# LM3S9C97 register map
File version: 7944
Registers are 32-bit, read-write, no defined reset value unless marked. A register's access mark holds for its fields unless they carry their own. Offsets are from the block's base; [hi:lo] are bit positions; {n}, {i} and the like mark numbered series.

## SYSCTL — Register map for SYSCTL peripheral
Base 0x400FE000; register names take the prefix SYSCTL
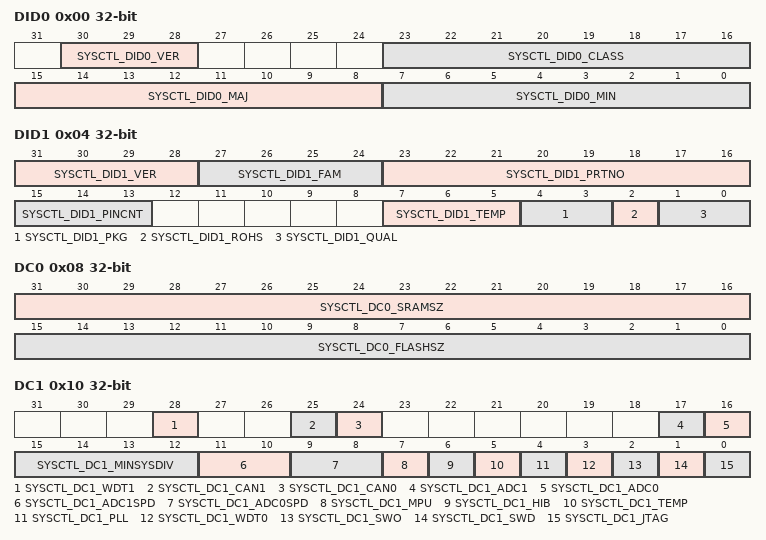
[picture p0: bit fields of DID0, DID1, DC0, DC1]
0x00 DID0 — Device Identification 0
  [30:28] SYSCTL_DID0_VER — DID0 Version
    1=Second version of the DID0 register format
  [23:16] SYSCTL_DID0_CLASS — Device Class
    6=SYSCTL_DID0_CLASS_FIRESTORM (Stellaris(R) Firestorm-class microcontrollers)
  [15:8] SYSCTL_DID0_MAJ — Major Revision
    0=SYSCTL_DID0_MAJ_REVA (Revision A (initial device)); 1=SYSCTL_DID0_MAJ_REVB (Revision B (first base layer revision)); 2=SYSCTL_DID0_MAJ_REVC (Revision C (second base layer revision))
  [7:0] SYSCTL_DID0_MIN — Minor Revision
    0=Initial device, or a major revision update; 1=First metal layer change; 2=Second metal layer change
0x04 DID1 — Device Identification 1
  [31:28] SYSCTL_DID1_VER — DID1 Version
    1=Second version of the DID1 register format
  [27:24] SYSCTL_DID1_FAM — Family
    0=SYSCTL_DID1_FAM_STELLARIS (Stellaris family of microcontollers, that is, all devices with external part numbers starting with LM3S)
  [23:16] SYSCTL_DID1_PRTNO — Part Number
    112=SYSCTL_DID1_PRTNO_9C97 (LM3S9C97)
  [15:13] SYSCTL_DID1_PINCNT — Package Pin Count
    2=100-pin package
  [7:5] SYSCTL_DID1_TEMP — Temperature Range
    0=SYSCTL_DID1_TEMP_C (Commercial temperature range (0C to 70C)); 1=SYSCTL_DID1_TEMP_I (Industrial temperature range (-40C to 85C)); 2=SYSCTL_DID1_TEMP_E (Extended temperature range (-40C to 105C))
  [4:3] SYSCTL_DID1_PKG — Package Type
    0=SYSCTL_DID1_PKG_SOIC (SOIC package); 1=SYSCTL_DID1_PKG_QFP (LQFP package); 2=SYSCTL_DID1_PKG_BGA (BGA package)
  [2] SYSCTL_DID1_ROHS — RoHS-Compliance
  [1:0] SYSCTL_DID1_QUAL — Qualification Status
    0=SYSCTL_DID1_QUAL_ES (Engineering Sample (unqualified)); 1=SYSCTL_DID1_QUAL_PP (Pilot Production (unqualified)); 2=SYSCTL_DID1_QUAL_FQ (Fully Qualified)
0x08 DC0 — Device Capabilities 0
  [31:16] SYSCTL_DC0_SRAMSZ — SRAM Size
    255=SYSCTL_DC0_SRAMSZ_64KB (64 KB of SRAM)
  [15:0] SYSCTL_DC0_FLASHSZ — Flash Size
    255=SYSCTL_DC0_FLASHSZ_512K (512 KB of Flash)
0x10 DC1 — Device Capabilities 1
  [28] SYSCTL_DC1_WDT1 — Watchdog Timer1 Present
  [25] SYSCTL_DC1_CAN1 — CAN Module 1 Present
  [24] SYSCTL_DC1_CAN0 — CAN Module 0 Present
  [17] SYSCTL_DC1_ADC1 — ADC Module 1 Present
  [16] SYSCTL_DC1_ADC0 — ADC Module 0 Present
  [15:12] SYSCTL_DC1_MINSYSDIV — System Clock Divider
    1=Divide VCO (400MHZ) by 5 minimum; 2=Divide VCO (400MHZ) by 2*2 + 2 = 6 minimum; 3=Specifies a 50-MHz CPU clock with a PLL divider of 4; 7=Specifies a 25-MHz clock with a PLL divider of 8; 9=Specifies a 20-MHz clock with a PLL divider of 10
  [11:10] SYSCTL_DC1_ADC1SPD — Max ADC1 Speed
    3=SYSCTL_DC1_ADC1SPD_1M (1M samples/second)
  [9:8] SYSCTL_DC1_ADC0SPD — Max ADC0 Speed
    3=SYSCTL_DC1_ADC0SPD_1M (1M samples/second)
  [7] SYSCTL_DC1_MPU — MPU Present
  [6] SYSCTL_DC1_HIB — Hibernation Module Present
  [5] SYSCTL_DC1_TEMP — Temp Sensor Present
  [4] SYSCTL_DC1_PLL — PLL Present
  [3] SYSCTL_DC1_WDT0 — Watchdog Timer 0 Present
  [2] SYSCTL_DC1_SWO — SWO Trace Port Present
  [1] SYSCTL_DC1_SWD — SWD Present
  [0] SYSCTL_DC1_JTAG — JTAG Present
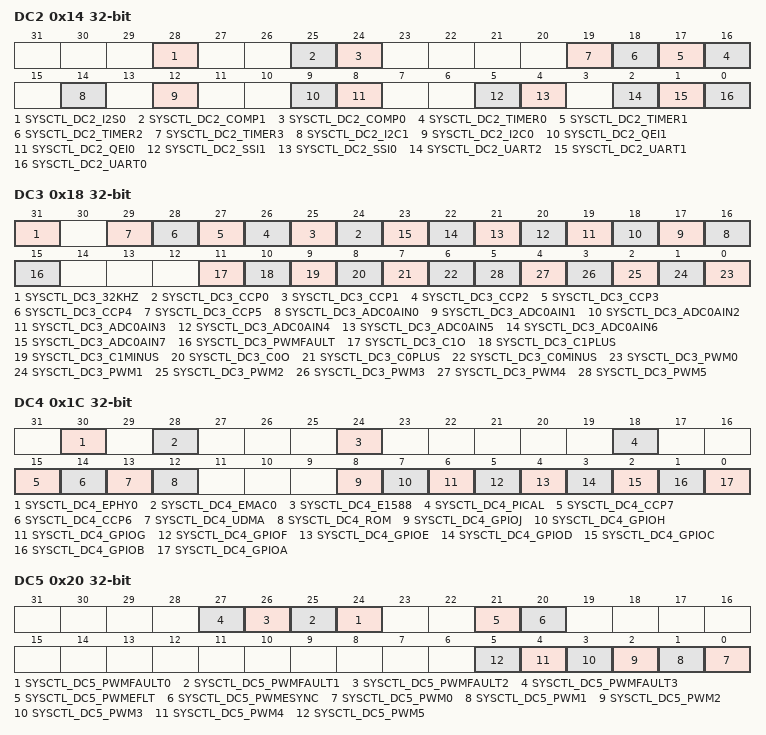
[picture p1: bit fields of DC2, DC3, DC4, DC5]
0x14 DC2 — Device Capabilities 2
  [28] SYSCTL_DC2_I2S0 — I2S Module 0 Present
  [25] SYSCTL_DC2_COMP1 — Analog Comparator 1 Present
  [24] SYSCTL_DC2_COMP0 — Analog Comparator 0 Present
  [n+16] SYSCTL_DC2_TIMER{n} (n=0..3) — Timer Module {n} Present
  [14] SYSCTL_DC2_I2C1 — I2C Module 1 Present
  [12] SYSCTL_DC2_I2C0 — I2C Module 0 Present
  [9] SYSCTL_DC2_QEI1 — QEI Module 1 Present
  [8] SYSCTL_DC2_QEI0 — QEI Module 0 Present
  [5] SYSCTL_DC2_SSI1 — SSI Module 1 Present
  [4] SYSCTL_DC2_SSI0 — SSI Module 0 Present
  [2] SYSCTL_DC2_UART2 — UART Module 2 Present
  [1] SYSCTL_DC2_UART1 — UART Module 1 Present
  [0] SYSCTL_DC2_UART0 — UART Module 0 Present
0x18 DC3 — Device Capabilities 3
  [31] SYSCTL_DC3_32KHZ — 32KHz Input Clock Available
  [n+24] SYSCTL_DC3_CCP{n} (n=0..5) — CCP{n} Pin Present
  [n+16] SYSCTL_DC3_ADC0AIN{n} (n=0..7) — ADC Module 0 AIN{n} Pin Present
  [15] SYSCTL_DC3_PWMFAULT — PWM Fault Pin Present
  [11] SYSCTL_DC3_C1O — C1o Pin Present
  [10] SYSCTL_DC3_C1PLUS — C1+ Pin Present
  [9] SYSCTL_DC3_C1MINUS — C1- Pin Present
  [8] SYSCTL_DC3_C0O — C0o Pin Present
  [7] SYSCTL_DC3_C0PLUS — C0+ Pin Present
  [6] SYSCTL_DC3_C0MINUS — C0- Pin Present
  [n] SYSCTL_DC3_PWM{n} (n=0..5) — PWM{n} Pin Present
0x1C DC4 — Device Capabilities 4
  [30] SYSCTL_DC4_EPHY0 — Ethernet PHY Layer 0 Present
  [28] SYSCTL_DC4_EMAC0 — Ethernet MAC Layer 0 Present
  [24] SYSCTL_DC4_E1588 — 1588 Capable
  [18] SYSCTL_DC4_PICAL — PIOSC Calibrate
  [15] SYSCTL_DC4_CCP7 — CCP7 Pin Present
  [14] SYSCTL_DC4_CCP6 — CCP6 Pin Present
  [13] SYSCTL_DC4_UDMA — Micro-DMA Module Present
  [12] SYSCTL_DC4_ROM — Internal Code ROM Present
  [8] SYSCTL_DC4_GPIOJ — GPIO Port J Present
  [7] SYSCTL_DC4_GPIOH — GPIO Port H Present
  [6] SYSCTL_DC4_GPIOG — GPIO Port G Present
  [5] SYSCTL_DC4_GPIOF — GPIO Port F Present
  [4] SYSCTL_DC4_GPIOE — GPIO Port E Present
  [3] SYSCTL_DC4_GPIOD — GPIO Port D Present
  [2] SYSCTL_DC4_GPIOC — GPIO Port C Present
  [1] SYSCTL_DC4_GPIOB — GPIO Port B Present
  [0] SYSCTL_DC4_GPIOA — GPIO Port A Present
0x20 DC5 — Device Capabilities 5
  [n+24] SYSCTL_DC5_PWMFAULT{n} (n=0..3) — PWM Fault {n} Pin Present
  [21] SYSCTL_DC5_PWMEFLT — PWM Extended Fault Active
  [20] SYSCTL_DC5_PWMESYNC — PWM Extended SYNC Active
  [n] SYSCTL_DC5_PWM{n} (n=0..5) — PWM{n} Pin Present
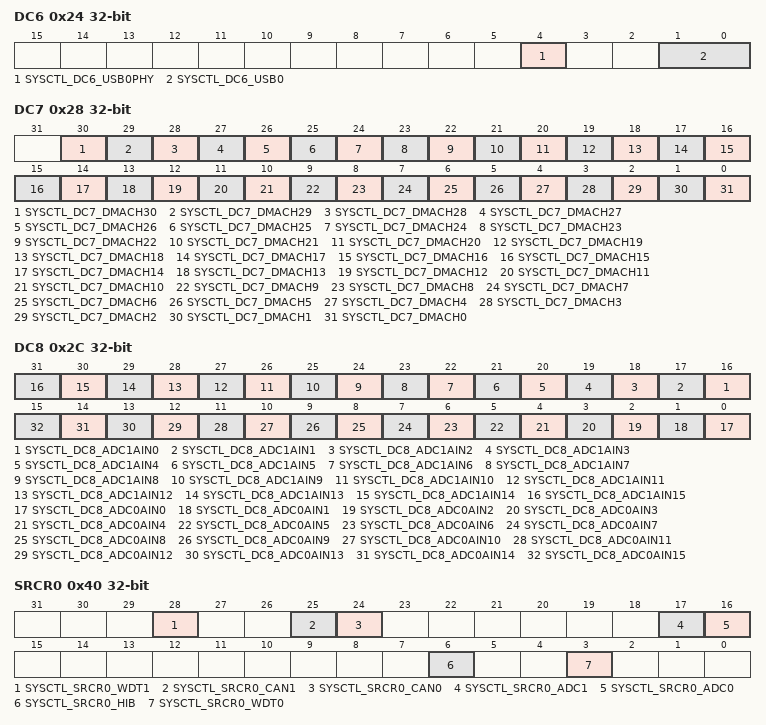
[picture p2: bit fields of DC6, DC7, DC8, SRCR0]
0x24 DC6 — Device Capabilities 6
  [4] SYSCTL_DC6_USB0PHY — USB Module 0 PHY Present
  [1:0] SYSCTL_DC6_USB0 — USB Module 0 Present
    3=SYSCTL_DC6_USB0_OTG (USB0 is OTG)
0x28 DC7 — Device Capabilities 7
  [30] SYSCTL_DC7_DMACH30 — SW
  [29] SYSCTL_DC7_DMACH29 — I2S0_TX / CAN1_TX
  [28] SYSCTL_DC7_DMACH28 — I2S0_RX / CAN1_RX
  [27] SYSCTL_DC7_DMACH27 — CAN1_TX / ADC1_SS3
  [26] SYSCTL_DC7_DMACH26 — CAN1_RX / ADC1_SS2
  [25] SYSCTL_DC7_DMACH25 — SSI1_TX / ADC1_SS1
  [24] SYSCTL_DC7_DMACH24 — SSI1_RX / ADC1_SS0
  [23] SYSCTL_DC7_DMACH23 — UART1_TX / CAN2_TX
  [22] SYSCTL_DC7_DMACH22 — UART1_RX / CAN2_RX
  [21] SYSCTL_DC7_DMACH21 — Timer1B / EPI0_WFIFO
  [20] SYSCTL_DC7_DMACH20 — Timer1A / EPI0_NBRFIFO
  [19] SYSCTL_DC7_DMACH19 — Timer0B / Timer1B
  [18] SYSCTL_DC7_DMACH18 — Timer0A / Timer1A
  [17] SYSCTL_DC7_DMACH17 — ADC0_SS3
  [16] SYSCTL_DC7_DMACH16 — ADC0_SS2
  [15] SYSCTL_DC7_DMACH15 — ADC0_SS1 / Timer2B
  [14] SYSCTL_DC7_DMACH14 — ADC0_SS0 / Timer2A
  [13] SYSCTL_DC7_DMACH13 — CAN0_TX / UART2_TX
  [12] SYSCTL_DC7_DMACH12 — CAN0_RX / UART2_RX
  [11] SYSCTL_DC7_DMACH11 — SSI0_TX / SSI1_TX
  [10] SYSCTL_DC7_DMACH10 — SSI0_RX / SSI1_RX
  [9] SYSCTL_DC7_DMACH9 — UART0_TX / UART1_TX
  [8] SYSCTL_DC7_DMACH8 — UART0_RX / UART1_RX
  [7] SYSCTL_DC7_DMACH7 — ETH_TX / Timer2B
  [6] SYSCTL_DC7_DMACH6 — ETH_RX / Timer2A
  [5] SYSCTL_DC7_DMACH5 — USB_EP3_TX / Timer2B
  [4] SYSCTL_DC7_DMACH4 — USB_EP3_RX / Timer2A
  [3] SYSCTL_DC7_DMACH3 — USB_EP2_TX / Timer3B
  [2] SYSCTL_DC7_DMACH2 — USB_EP2_RX / Timer3A
  [1] SYSCTL_DC7_DMACH1 — USB_EP1_TX / UART2_TX
  [0] SYSCTL_DC7_DMACH0 — USB_EP1_RX / UART2_RX
0x2C DC8 — Device Capabilities 8 ADC Channels
  [n+16] SYSCTL_DC8_ADC1AIN{n} (n=0..15) — ADC Module 1 AIN{n} Pin Present
  [n] SYSCTL_DC8_ADC0AIN{n} (n=0..15) — ADC Module 0 AIN{n} Pin Present
0x30 PBORCTL — Brown-Out Reset Control
  [1] SYSCTL_PBORCTL_BORIOR — BOR Interrupt or Reset
0x40 SRCR0 — Software Reset Control 0
  [28] SYSCTL_SRCR0_WDT1 — WDT1 Reset Control
  [25] SYSCTL_SRCR0_CAN1 — CAN1 Reset Control
  [24] SYSCTL_SRCR0_CAN0 — CAN0 Reset Control
  [17] SYSCTL_SRCR0_ADC1 — ADC1 Reset Control
  [16] SYSCTL_SRCR0_ADC0 — ADC0 Reset Control
  [6] SYSCTL_SRCR0_HIB — HIB Reset Control
  [3] SYSCTL_SRCR0_WDT0 — WDT0 Reset Control
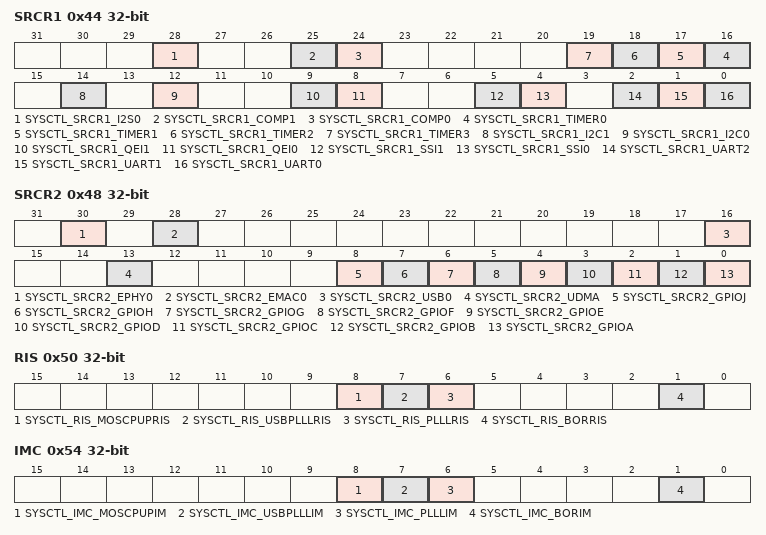
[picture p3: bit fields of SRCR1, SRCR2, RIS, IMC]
0x44 SRCR1 — Software Reset Control 1
  [28] SYSCTL_SRCR1_I2S0 — I2S0 Reset Control
  [25] SYSCTL_SRCR1_COMP1 — Analog Comp 1 Reset Control
  [24] SYSCTL_SRCR1_COMP0 — Analog Comp 0 Reset Control
  [n+16] SYSCTL_SRCR1_TIMER{n} (n=0..3) — Timer {n} Reset Control
  [14] SYSCTL_SRCR1_I2C1 — I2C1 Reset Control
  [12] SYSCTL_SRCR1_I2C0 — I2C0 Reset Control
  [9] SYSCTL_SRCR1_QEI1 — QEI1 Reset Control
  [8] SYSCTL_SRCR1_QEI0 — QEI0 Reset Control
  [5] SYSCTL_SRCR1_SSI1 — SSI1 Reset Control
  [4] SYSCTL_SRCR1_SSI0 — SSI0 Reset Control
  [2] SYSCTL_SRCR1_UART2 — UART2 Reset Control
  [1] SYSCTL_SRCR1_UART1 — UART1 Reset Control
  [0] SYSCTL_SRCR1_UART0 — UART0 Reset Control
0x48 SRCR2 — Software Reset Control 2
  [30] SYSCTL_SRCR2_EPHY0 — PHY0 Reset Control
  [28] SYSCTL_SRCR2_EMAC0 — MAC0 Reset Control
  [16] SYSCTL_SRCR2_USB0 — USB0 Reset Control
  [13] SYSCTL_SRCR2_UDMA — Micro-DMA Reset Control
  [8] SYSCTL_SRCR2_GPIOJ — Port J Reset Control
  [7] SYSCTL_SRCR2_GPIOH — Port H Reset Control
  [6] SYSCTL_SRCR2_GPIOG — Port G Reset Control
  [5] SYSCTL_SRCR2_GPIOF — Port F Reset Control
  [4] SYSCTL_SRCR2_GPIOE — Port E Reset Control
  [3] SYSCTL_SRCR2_GPIOD — Port D Reset Control
  [2] SYSCTL_SRCR2_GPIOC — Port C Reset Control
  [1] SYSCTL_SRCR2_GPIOB — Port B Reset Control
  [0] SYSCTL_SRCR2_GPIOA — Port A Reset Control
0x50 RIS — Raw Interrupt Status
  [8] SYSCTL_RIS_MOSCPUPRIS — MOSC Power Up Raw Interrupt Status
  [7] SYSCTL_RIS_USBPLLLRIS — USB PLL Lock Raw Interrupt Status
  [6] SYSCTL_RIS_PLLLRIS — PLL Lock Raw Interrupt Status
  [1] SYSCTL_RIS_BORRIS — Brown-Out Reset Raw Interrupt Status
0x54 IMC — Interrupt Mask Control
  [8] SYSCTL_IMC_MOSCPUPIM — MOSC Power Up Interrupt Mask
  [7] SYSCTL_IMC_USBPLLLIM — USB PLL Lock Interrupt Mask
  [6] SYSCTL_IMC_PLLLIM — PLL Lock Interrupt Mask
  [1] SYSCTL_IMC_BORIM — Brown-Out Reset Interrupt Mask
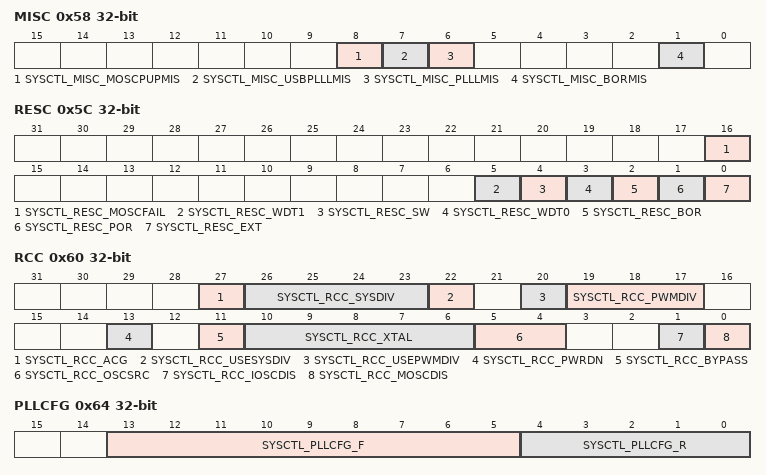
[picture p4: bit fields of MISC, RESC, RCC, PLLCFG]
0x58 MISC — Masked Interrupt Status and Clear
  [8] SYSCTL_MISC_MOSCPUPMIS — MOSC Power Up Masked Interrupt Status
  [7] SYSCTL_MISC_USBPLLLMIS — USB PLL Lock Masked Interrupt Status
  [6] SYSCTL_MISC_PLLLMIS — PLL Lock Masked Interrupt Status
  [1] SYSCTL_MISC_BORMIS — BOR Masked Interrupt Status
0x5C RESC — Reset Cause
  [16] SYSCTL_RESC_MOSCFAIL — MOSC Failure Reset
  [5] SYSCTL_RESC_WDT1 — Watchdog Timer 1 Reset
  [4] SYSCTL_RESC_SW — Software Reset
  [3] SYSCTL_RESC_WDT0 — Watchdog Timer 0 Reset
  [2] SYSCTL_RESC_BOR — Brown-Out Reset
  [1] SYSCTL_RESC_POR — Power-On Reset
  [0] SYSCTL_RESC_EXT — External Reset
0x60 RCC — Run-Mode Clock Configuration
  [27] SYSCTL_RCC_ACG — Auto Clock Gating
  [26:23] SYSCTL_RCC_SYSDIV — System Clock Divisor
  [22] SYSCTL_RCC_USESYSDIV — Enable System Clock Divider
  [20] SYSCTL_RCC_USEPWMDIV — Enable PWM Clock Divisor
  [19:17] SYSCTL_RCC_PWMDIV — PWM Unit Clock Divisor
    0=PWM clock /2; 1=PWM clock /4; 2=PWM clock /8; 3=PWM clock /16; 4=PWM clock /32; 5=PWM clock /64
  [13] SYSCTL_RCC_PWRDN — PLL Power Down
  [11] SYSCTL_RCC_BYPASS — PLL Bypass
  [10:6] SYSCTL_RCC_XTAL — Crystal Value
    0=SYSCTL_RCC_XTAL_1MHZ (1 MHz); 1=SYSCTL_RCC_XTAL_1_84MHZ (1.8432 MHz); 2=SYSCTL_RCC_XTAL_2MHZ (2 MHz); 3=SYSCTL_RCC_XTAL_2_45MHZ (2.4576 MHz); 4=SYSCTL_RCC_XTAL_3_57MHZ (3.579545 MHz); 5=SYSCTL_RCC_XTAL_3_68MHZ (3.6864 MHz); 6=SYSCTL_RCC_XTAL_4MHZ (4 MHz); 7=SYSCTL_RCC_XTAL_4_09MHZ (4.096 MHz); 8=SYSCTL_RCC_XTAL_4_91MHZ (4.9152 MHz); 9=SYSCTL_RCC_XTAL_5MHZ (5 MHz); 10=SYSCTL_RCC_XTAL_5_12MHZ (5.12 MHz); 11=SYSCTL_RCC_XTAL_6MHZ (6 MHz); 12=SYSCTL_RCC_XTAL_6_14MHZ (6.144 MHz); 13=SYSCTL_RCC_XTAL_7_37MHZ (7.3728 MHz); 14=SYSCTL_RCC_XTAL_8MHZ (8 MHz); 15=SYSCTL_RCC_XTAL_8_19MHZ (8.192 MHz); 16=SYSCTL_RCC_XTAL_10MHZ (10 MHz); 17=SYSCTL_RCC_XTAL_12MHZ (12 MHz); 18=SYSCTL_RCC_XTAL_12_2MHZ (12.288 MHz); 19=SYSCTL_RCC_XTAL_13_5MHZ (13.56 MHz); 20=SYSCTL_RCC_XTAL_14_3MHZ (14.31818 MHz); 21=SYSCTL_RCC_XTAL_16MHZ (16 MHz); 22=SYSCTL_RCC_XTAL_16_3MHZ (16.384 MHz)
  [5:4] SYSCTL_RCC_OSCSRC — Oscillator Source
    0=SYSCTL_RCC_OSCSRC_MAIN (MOSC); 1=SYSCTL_RCC_OSCSRC_INT (IOSC); 2=SYSCTL_RCC_OSCSRC_INT4 (IOSC/4); 3=30 kHz
  [1] SYSCTL_RCC_IOSCDIS — Internal Oscillator Disable
  [0] SYSCTL_RCC_MOSCDIS — Main Oscillator Disable
0x64 PLLCFG — XTAL to PLL Translation
  [13:5] SYSCTL_PLLCFG_F — PLL F Value
  [4:0] SYSCTL_PLLCFG_R — PLL R Value
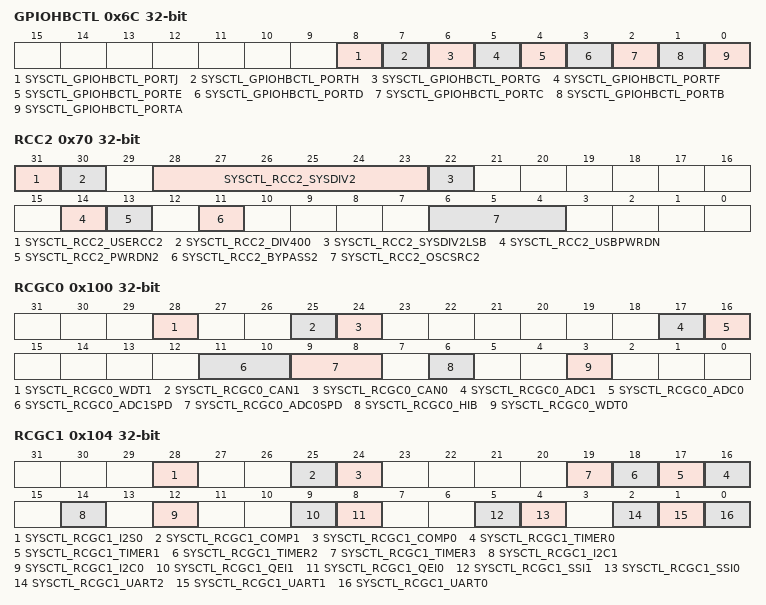
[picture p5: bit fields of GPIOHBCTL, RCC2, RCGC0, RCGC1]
0x6C GPIOHBCTL — GPIO High-Performance Bus Control
  [8] SYSCTL_GPIOHBCTL_PORTJ — Port J Advanced High-Performance Bus
  [7] SYSCTL_GPIOHBCTL_PORTH — Port H Advanced High-Performance Bus
  [6] SYSCTL_GPIOHBCTL_PORTG — Port G Advanced High-Performance Bus
  [5] SYSCTL_GPIOHBCTL_PORTF — Port F Advanced High-Performance Bus
  [4] SYSCTL_GPIOHBCTL_PORTE — Port E Advanced High-Performance Bus
  [3] SYSCTL_GPIOHBCTL_PORTD — Port D Advanced High-Performance Bus
  [2] SYSCTL_GPIOHBCTL_PORTC — Port C Advanced High-Performance Bus
  [1] SYSCTL_GPIOHBCTL_PORTB — Port B Advanced High-Performance Bus
  [0] SYSCTL_GPIOHBCTL_PORTA — Port A Advanced High-Performance Bus
0x70 RCC2 — Run-Mode Clock Configuration 2
  [31] SYSCTL_RCC2_USERCC2 — Use RCC2
  [30] SYSCTL_RCC2_DIV400 — Divide PLL as 400 MHz vs. 200 MHz
  [28:23] SYSCTL_RCC2_SYSDIV2 — System Clock Divisor 2
    {v}=System clock /{v+1} (v=1..63)
  [22] SYSCTL_RCC2_SYSDIV2LSB — Additional LSB for SYSDIV2
  [14] SYSCTL_RCC2_USBPWRDN — Power-Down USB PLL
  [13] SYSCTL_RCC2_PWRDN2 — Power-Down PLL 2
  [11] SYSCTL_RCC2_BYPASS2 — PLL Bypass 2
  [6:4] SYSCTL_RCC2_OSCSRC2 — Oscillator Source 2
    0=SYSCTL_RCC2_OSCSRC2_MO (MOSC); 1=SYSCTL_RCC2_OSCSRC2_IO (PIOSC); 2=SYSCTL_RCC2_OSCSRC2_IO4 (PIOSC/4); 3=30 kHz; 6=4.194304 MHz; 7=32.768 kHz
0x7C MOSCCTL — Main Oscillator Control
  [0] SYSCTL_MOSCCTL_CVAL — Clock Validation for MOSC
0x100 RCGC0 — Run Mode Clock Gating Control Register 0
  [28] SYSCTL_RCGC0_WDT1 — WDT1 Clock Gating Control
  [25] SYSCTL_RCGC0_CAN1 — CAN1 Clock Gating Control
  [24] SYSCTL_RCGC0_CAN0 — CAN0 Clock Gating Control
  [17] SYSCTL_RCGC0_ADC1 — ADC1 Clock Gating Control
  [16] SYSCTL_RCGC0_ADC0 — ADC0 Clock Gating Control
  [11:10] SYSCTL_RCGC0_ADC1SPD — ADC1 Sample Speed
    0=SYSCTL_RCGC0_ADC1SPD_125K (125K samples/second); 1=SYSCTL_RCGC0_ADC1SPD_250K (250K samples/second); 2=SYSCTL_RCGC0_ADC1SPD_500K (500K samples/second); 3=SYSCTL_RCGC0_ADC1SPD_1M (1M samples/second)
  [9:8] SYSCTL_RCGC0_ADC0SPD — ADC0 Sample Speed
    0=SYSCTL_RCGC0_ADC0SPD_125K (125K samples/second); 1=SYSCTL_RCGC0_ADC0SPD_250K (250K samples/second); 2=SYSCTL_RCGC0_ADC0SPD_500K (500K samples/second); 3=SYSCTL_RCGC0_ADC0SPD_1M (1M samples/second)
  [6] SYSCTL_RCGC0_HIB — HIB Clock Gating Control
  [3] SYSCTL_RCGC0_WDT0 — WDT0 Clock Gating Control
0x104 RCGC1 — Run Mode Clock Gating Control Register 1
  [28] SYSCTL_RCGC1_I2S0 — I2S0 Clock Gating
  [25] SYSCTL_RCGC1_COMP1 — Analog Comparator 1 Clock Gating
  [24] SYSCTL_RCGC1_COMP0 — Analog Comparator 0 Clock Gating
  [n+16] SYSCTL_RCGC1_TIMER{n} (n=0..3) — Timer {n} Clock Gating Control
  [14] SYSCTL_RCGC1_I2C1 — I2C1 Clock Gating Control
  [12] SYSCTL_RCGC1_I2C0 — I2C0 Clock Gating Control
  [9] SYSCTL_RCGC1_QEI1 — QEI1 Clock Gating Control
  [8] SYSCTL_RCGC1_QEI0 — QEI0 Clock Gating Control
  [5] SYSCTL_RCGC1_SSI1 — SSI1 Clock Gating Control
  [4] SYSCTL_RCGC1_SSI0 — SSI0 Clock Gating Control
  [2] SYSCTL_RCGC1_UART2 — UART2 Clock Gating Control
  [1] SYSCTL_RCGC1_UART1 — UART1 Clock Gating Control
  [0] SYSCTL_RCGC1_UART0 — UART0 Clock Gating Control
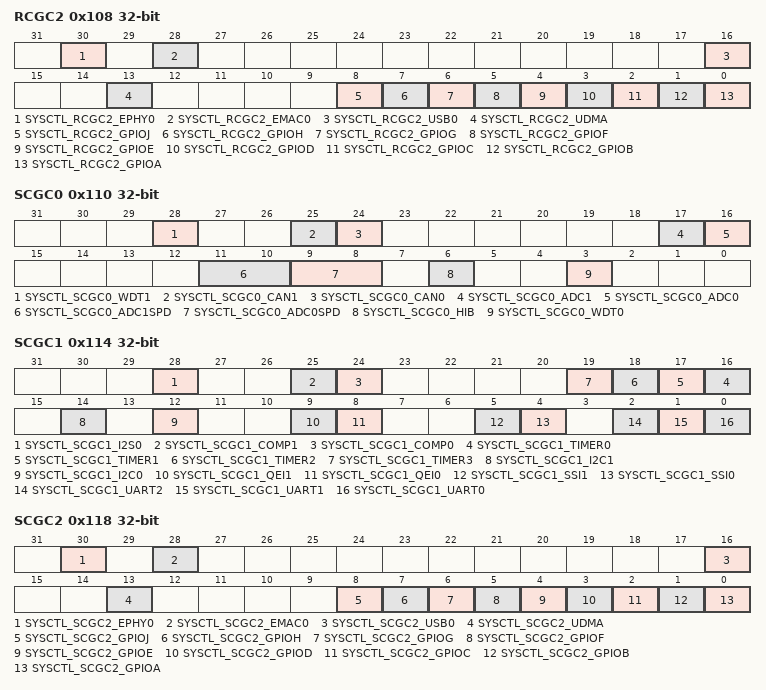
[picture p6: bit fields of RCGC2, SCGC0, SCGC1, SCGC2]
0x108 RCGC2 — Run Mode Clock Gating Control Register 2
  [30] SYSCTL_RCGC2_EPHY0 — PHY0 Clock Gating Control
  [28] SYSCTL_RCGC2_EMAC0 — MAC0 Clock Gating Control
  [16] SYSCTL_RCGC2_USB0 — USB0 Clock Gating Control
  [13] SYSCTL_RCGC2_UDMA — Micro-DMA Clock Gating Control
  [8] SYSCTL_RCGC2_GPIOJ — Port J Clock Gating Control
  [7] SYSCTL_RCGC2_GPIOH — Port H Clock Gating Control
  [6] SYSCTL_RCGC2_GPIOG — Port G Clock Gating Control
  [5] SYSCTL_RCGC2_GPIOF — Port F Clock Gating Control
  [4] SYSCTL_RCGC2_GPIOE — Port E Clock Gating Control
  [3] SYSCTL_RCGC2_GPIOD — Port D Clock Gating Control
  [2] SYSCTL_RCGC2_GPIOC — Port C Clock Gating Control
  [1] SYSCTL_RCGC2_GPIOB — Port B Clock Gating Control
  [0] SYSCTL_RCGC2_GPIOA — Port A Clock Gating Control
0x110 SCGC0 — Sleep Mode Clock Gating Control Register 0
  [28] SYSCTL_SCGC0_WDT1 — WDT1 Clock Gating Control
  [25] SYSCTL_SCGC0_CAN1 — CAN1 Clock Gating Control
  [24] SYSCTL_SCGC0_CAN0 — CAN0 Clock Gating Control
  [17] SYSCTL_SCGC0_ADC1 — ADC1 Clock Gating Control
  [16] SYSCTL_SCGC0_ADC0 — ADC0 Clock Gating Control
  [11:10] SYSCTL_SCGC0_ADC1SPD — ADC1 Sample Speed
    0=SYSCTL_SCGC0_ADC1SPD_125K (125K samples/second); 1=SYSCTL_SCGC0_ADC1SPD_250K (250K samples/second); 2=SYSCTL_SCGC0_ADC1SPD_500K (500K samples/second); 3=SYSCTL_SCGC0_ADC1SPD_1M (1M samples/second)
  [9:8] SYSCTL_SCGC0_ADC0SPD — ADC0 Sample Speed
    0=SYSCTL_SCGC0_ADC0SPD_125K (125K samples/second); 1=SYSCTL_SCGC0_ADC0SPD_250K (250K samples/second); 2=SYSCTL_SCGC0_ADC0SPD_500K (500K samples/second); 3=SYSCTL_SCGC0_ADC0SPD_1M (1M samples/second)
  [6] SYSCTL_SCGC0_HIB — HIB Clock Gating Control
  [3] SYSCTL_SCGC0_WDT0 — WDT0 Clock Gating Control
0x114 SCGC1 — Sleep Mode Clock Gating Control Register 1
  [28] SYSCTL_SCGC1_I2S0 — I2S0 Clock Gating
  [25] SYSCTL_SCGC1_COMP1 — Analog Comparator 1 Clock Gating
  [24] SYSCTL_SCGC1_COMP0 — Analog Comparator 0 Clock Gating
  [n+16] SYSCTL_SCGC1_TIMER{n} (n=0..3) — Timer {n} Clock Gating Control
  [14] SYSCTL_SCGC1_I2C1 — I2C1 Clock Gating Control
  [12] SYSCTL_SCGC1_I2C0 — I2C0 Clock Gating Control
  [9] SYSCTL_SCGC1_QEI1 — QEI1 Clock Gating Control
  [8] SYSCTL_SCGC1_QEI0 — QEI0 Clock Gating Control
  [5] SYSCTL_SCGC1_SSI1 — SSI1 Clock Gating Control
  [4] SYSCTL_SCGC1_SSI0 — SSI0 Clock Gating Control
  [2] SYSCTL_SCGC1_UART2 — UART2 Clock Gating Control
  [1] SYSCTL_SCGC1_UART1 — UART1 Clock Gating Control
  [0] SYSCTL_SCGC1_UART0 — UART0 Clock Gating Control
0x118 SCGC2 — Sleep Mode Clock Gating Control Register 2
  [30] SYSCTL_SCGC2_EPHY0 — PHY0 Clock Gating Control
  [28] SYSCTL_SCGC2_EMAC0 — MAC0 Clock Gating Control
  [16] SYSCTL_SCGC2_USB0 — USB0 Clock Gating Control
  [13] SYSCTL_SCGC2_UDMA — Micro-DMA Clock Gating Control
  [8] SYSCTL_SCGC2_GPIOJ — Port J Clock Gating Control
  [7] SYSCTL_SCGC2_GPIOH — Port H Clock Gating Control
  [6] SYSCTL_SCGC2_GPIOG — Port G Clock Gating Control
  [5] SYSCTL_SCGC2_GPIOF — Port F Clock Gating Control
  [4] SYSCTL_SCGC2_GPIOE — Port E Clock Gating Control
  [3] SYSCTL_SCGC2_GPIOD — Port D Clock Gating Control
  [2] SYSCTL_SCGC2_GPIOC — Port C Clock Gating Control
  [1] SYSCTL_SCGC2_GPIOB — Port B Clock Gating Control
  [0] SYSCTL_SCGC2_GPIOA — Port A Clock Gating Control
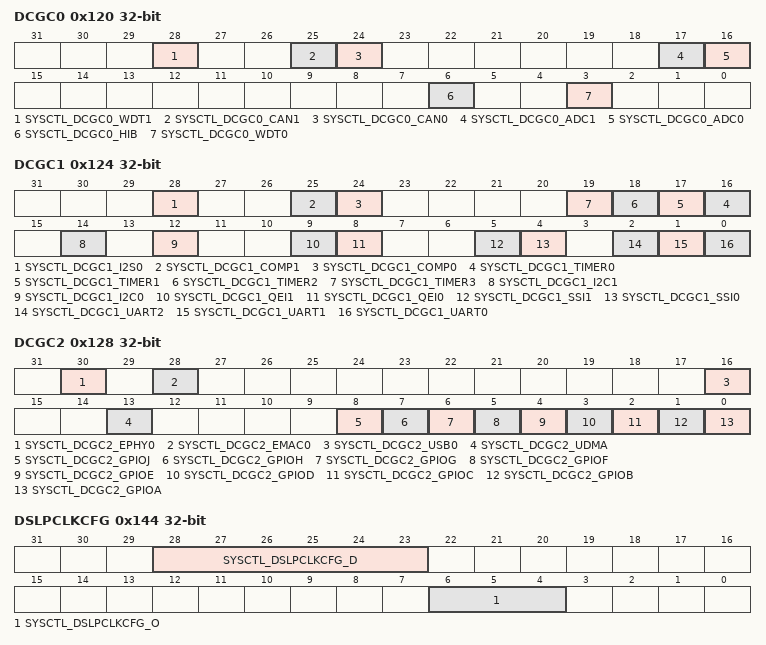
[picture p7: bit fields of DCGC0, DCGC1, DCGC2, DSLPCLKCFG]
0x120 DCGC0 — Deep Sleep Mode Clock Gating Control Register 0
  [28] SYSCTL_DCGC0_WDT1 — WDT1 Clock Gating Control
  [25] SYSCTL_DCGC0_CAN1 — CAN1 Clock Gating Control
  [24] SYSCTL_DCGC0_CAN0 — CAN0 Clock Gating Control
  [17] SYSCTL_DCGC0_ADC1 — ADC1 Clock Gating Control
  [16] SYSCTL_DCGC0_ADC0 — ADC0 Clock Gating Control
  [6] SYSCTL_DCGC0_HIB — HIB Clock Gating Control
  [3] SYSCTL_DCGC0_WDT0 — WDT0 Clock Gating Control
0x124 DCGC1 — Deep-Sleep Mode Clock Gating Control Register 1
  [28] SYSCTL_DCGC1_I2S0 — I2S0 Clock Gating
  [25] SYSCTL_DCGC1_COMP1 — Analog Comparator 1 Clock Gating
  [24] SYSCTL_DCGC1_COMP0 — Analog Comparator 0 Clock Gating
  [n+16] SYSCTL_DCGC1_TIMER{n} (n=0..3) — Timer {n} Clock Gating Control
  [14] SYSCTL_DCGC1_I2C1 — I2C1 Clock Gating Control
  [12] SYSCTL_DCGC1_I2C0 — I2C0 Clock Gating Control
  [9] SYSCTL_DCGC1_QEI1 — QEI1 Clock Gating Control
  [8] SYSCTL_DCGC1_QEI0 — QEI0 Clock Gating Control
  [5] SYSCTL_DCGC1_SSI1 — SSI1 Clock Gating Control
  [4] SYSCTL_DCGC1_SSI0 — SSI0 Clock Gating Control
  [2] SYSCTL_DCGC1_UART2 — UART2 Clock Gating Control
  [1] SYSCTL_DCGC1_UART1 — UART1 Clock Gating Control
  [0] SYSCTL_DCGC1_UART0 — UART0 Clock Gating Control
0x128 DCGC2 — Deep Sleep Mode Clock Gating Control Register 2
  [30] SYSCTL_DCGC2_EPHY0 — PHY0 Clock Gating Control
  [28] SYSCTL_DCGC2_EMAC0 — MAC0 Clock Gating Control
  [16] SYSCTL_DCGC2_USB0 — USB0 Clock Gating Control
  [13] SYSCTL_DCGC2_UDMA — Micro-DMA Clock Gating Control
  [8] SYSCTL_DCGC2_GPIOJ — Port J Clock Gating Control
  [7] SYSCTL_DCGC2_GPIOH — Port H Clock Gating Control
  [6] SYSCTL_DCGC2_GPIOG — Port G Clock Gating Control
  [5] SYSCTL_DCGC2_GPIOF — Port F Clock Gating Control
  [4] SYSCTL_DCGC2_GPIOE — Port E Clock Gating Control
  [3] SYSCTL_DCGC2_GPIOD — Port D Clock Gating Control
  [2] SYSCTL_DCGC2_GPIOC — Port C Clock Gating Control
  [1] SYSCTL_DCGC2_GPIOB — Port B Clock Gating Control
  [0] SYSCTL_DCGC2_GPIOA — Port A Clock Gating Control
0x144 DSLPCLKCFG — Deep Sleep Clock Configuration
  [28:23] SYSCTL_DSLPCLKCFG_D — Divider Field Override
    {v}=System clock /{v+1} (v=0..3); 63=System clock /64
  [6:4] SYSCTL_DSLPCLKCFG_O — Clock Source
    0=SYSCTL_DSLPCLKCFG_O_IGN (MOSC); 1=SYSCTL_DSLPCLKCFG_O_IO (PIOSC); 3=30 kHz; 7=32.768 kHz
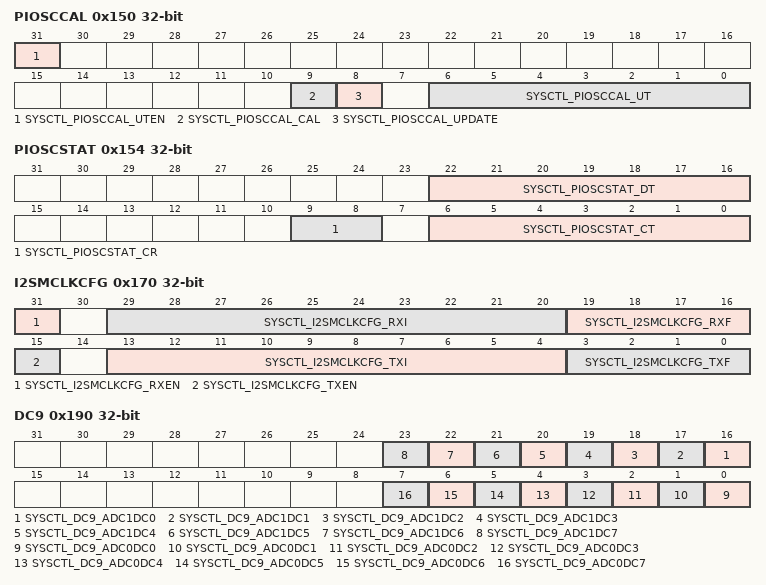
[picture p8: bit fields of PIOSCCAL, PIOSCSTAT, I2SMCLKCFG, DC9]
0x150 PIOSCCAL — Precision Internal Oscillator Calibration
  [31] SYSCTL_PIOSCCAL_UTEN — Use User Trim Value
  [9] SYSCTL_PIOSCCAL_CAL — Start Calibration
  [8] SYSCTL_PIOSCCAL_UPDATE — Update Trim
  [6:0] SYSCTL_PIOSCCAL_UT — User Trim Value
0x154 PIOSCSTAT — Precision Internal Oscillator Statistics
  [22:16] SYSCTL_PIOSCSTAT_DT — Default Trim Value
  [9:8] SYSCTL_PIOSCSTAT_CR — Calibration Result
    0=SYSCTL_PIOSCSTAT_CRNONE (Calibration has not been attempted); 1=SYSCTL_PIOSCSTAT_CRPASS (The last calibration operation completed to meet 1% accuracy); 2=SYSCTL_PIOSCSTAT_CRFAIL (The last calibration operation failed to meet 1% accuracy)
  [6:0] SYSCTL_PIOSCSTAT_CT — Calibration Trim Value
0x170 I2SMCLKCFG — I2S MCLK Configuration
  [31] SYSCTL_I2SMCLKCFG_RXEN — RX Clock Enable
  [29:20] SYSCTL_I2SMCLKCFG_RXI — RX Clock Integer Input
  [19:16] SYSCTL_I2SMCLKCFG_RXF — RX Clock Fractional Input
  [15] SYSCTL_I2SMCLKCFG_TXEN — TX Clock Enable
  [13:4] SYSCTL_I2SMCLKCFG_TXI — TX Clock Integer Input
  [3:0] SYSCTL_I2SMCLKCFG_TXF — TX Clock Fractional Input
0x190 DC9 — Device Capabilities 9 ADC Digital Comparators
  [n+16] SYSCTL_DC9_ADC1DC{n} (n=0..7) — ADC1 DC{n} Present
  [n] SYSCTL_DC9_ADC0DC{n} (n=0..7) — ADC0 DC{n} Present
0x1A0 NVMSTAT — Non-Volatile Memory Information
  [0] SYSCTL_NVMSTAT_FWB — 32 Word Flash Write Buffer Active
